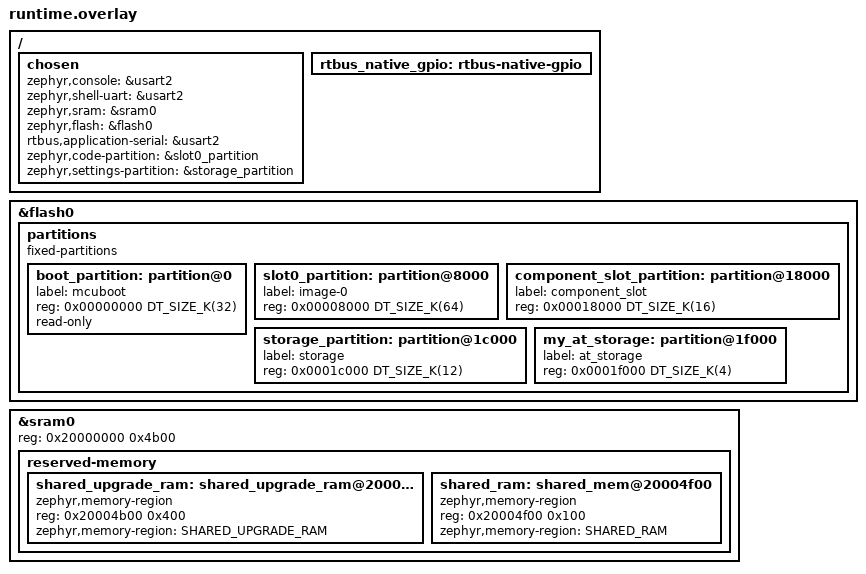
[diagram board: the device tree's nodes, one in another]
/ {
	chosen {
		zephyr,console = &usart2;
		zephyr,shell-uart = &usart2;
		zephyr,sram = &sram0;
		zephyr,flash = &flash0;
		rtbus,application-serial = &usart2;
		zephyr,code-partition = &slot0_partition;
		zephyr,settings-partition = &storage_partition;
	};

	rtbus_native_gpio: rtbus-native-gpio {
		/*
		 * Application GPIO export map.
		 *
		 * Only board-owned pins that are safe for native applications should
		 * be listed here. Leaving this empty avoids exposing runtime,
		 * peripheral, wake, and low-power pins as raw GPIO ABI.
		 */
	};
};

&flash0 {
	partitions {
		compatible = "fixed-partitions";
		#address-cells = <1>;
		#size-cells = <1>;

		boot_partition: partition@0 {
			label = "mcuboot";
			reg = <0x00000000 DT_SIZE_K(32)>;
			read-only;
		};

		slot0_partition: partition@8000 {
			label = "image-0";
			reg = <0x00008000 DT_SIZE_K(64)>;
		};

		component_slot_partition: partition@18000 {
			label = "component_slot";
			reg = <0x00018000 DT_SIZE_K(16)>;
		};

		storage_partition: partition@1c000 {
			label = "storage";
			reg = <0x0001c000 DT_SIZE_K(12)>;
		};

		my_at_storage: partition@1f000 {
			label = "at_storage";
			reg = <0x0001f000 DT_SIZE_K(4)>;
		};
	};
};

&sram0 {
	reg = <0x20000000 0x4b00>;

	reserved-memory {
		#address-cells = <1>;
		#size-cells = <1>;
		ranges;

		shared_upgrade_ram: shared_upgrade_ram@20004b00 {
			compatible = "zephyr,memory-region";
			reg = <0x20004b00 0x400>;
			zephyr,memory-region = "SHARED_UPGRADE_RAM";
		};

		shared_ram: shared_mem@20004f00 {
			compatible = "zephyr,memory-region";
			reg = <0x20004f00 0x100>;
			zephyr,memory-region = "SHARED_RAM";
		};
	};
};
